AUTOSAR XML (schema 4-2-2)
package /STELLANTIS/EPT/ASWCs
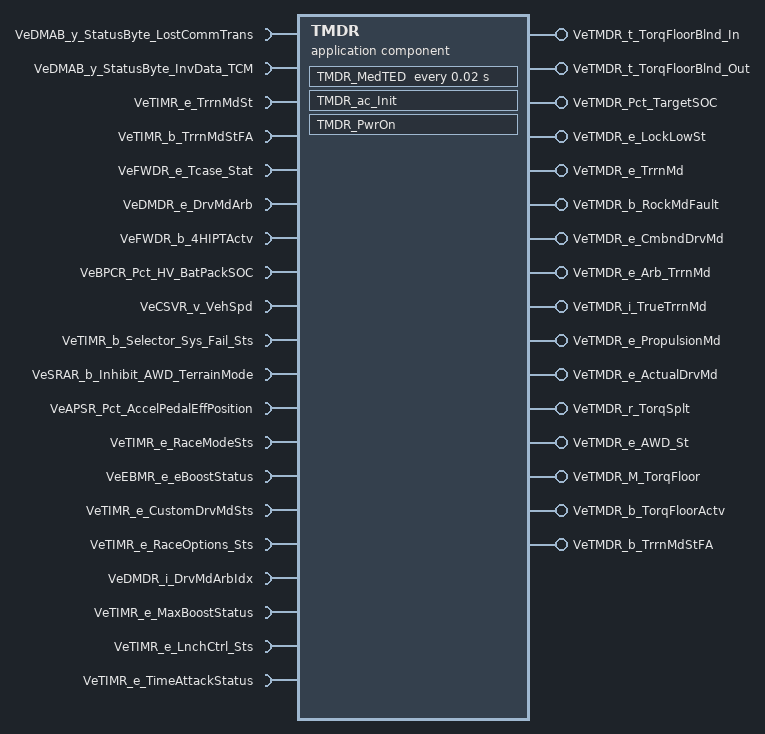
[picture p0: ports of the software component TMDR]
  application sw component type TMDR
    20 x require port:
      VeDMAB_y_StatusByte_LostCommTrans: variation-point={short-label=vpVeDMAB_y_StatusByte_LostCommTrans, sw-syscond=1}, nonqueued-receiver-com-spec{data-element=Value, init-value=0}, required-interface=VeDMAB_y_StatusByte_LostCommTrans
      VeDMAB_y_StatusByte_InvData_TCM: variation-point={short-label=vpVeDMAB_y_StatusByte_InvData_TCM, sw-syscond=1}, nonqueued-receiver-com-spec{data-element=Value, init-value=0}, required-interface=VeDMAB_y_StatusByte_InvData_TCM
      VeTIMR_e_TrrnMdSt: variation-point={short-label=vpVeTIMR_e_TrrnMdSt, sw-syscond=1}, nonqueued-receiver-com-spec{data-element=Value, init-value=CeTMDR_e_NotDefine}, required-interface=VeTIMR_e_TrrnMdSt
      VeTIMR_b_TrrnMdStFA: variation-point={short-label=vpVeTIMR_b_TrrnMdStFA, sw-syscond=1}, nonqueued-receiver-com-spec{data-element=Value, init-value=0}, required-interface=VeTIMR_b_TrrnMdStFA
      VeFWDR_e_Tcase_Stat: variation-point={short-label=vpVeFWDR_e_Tcase_Stat, sw-syscond=1}, nonqueued-receiver-com-spec{data-element=Value, init-value=CeFWDR_e_ShiftINProg}, required-interface=VeFWDR_e_Tcase_Stat
      VeDMDR_e_DrvMdArb: variation-point={short-label=vpVeDMDR_e_DrvMdArb, sw-syscond=1}, nonqueued-receiver-com-spec{data-element=Value, init-value=CeDMDR_e_NoDrvMd}, required-interface=VeDMDR_e_DrvMdArb
      VeFWDR_b_4HIPTActv: variation-point={short-label=vpVeFWDR_b_4HIPTActv, sw-syscond=1}, nonqueued-receiver-com-spec{data-element=Value, init-value=0}, required-interface=VeFWDR_b_4HIPTActv
      VeBPCR_Pct_HV_BatPackSOC: variation-point={short-label=vpVeBPCR_Pct_HV_BatPackSOC, sw-syscond=1}, nonqueued-receiver-com-spec{data-element=Value, init-value=0}, required-interface=VeBPCR_Pct_HV_BatPackSOC
      VeCSVR_v_VehSpd: variation-point={short-label=vpVeCSVR_v_VehSpd, sw-syscond=1}, nonqueued-receiver-com-spec{data-element=Value, init-value=0}, required-interface=VeCSVR_v_VehSpd
      VeTIMR_b_Selector_Sys_Fail_Sts: variation-point={short-label=vpVeTIMR_b_Selector_Sys_Fail_Sts, sw-syscond=1}, nonqueued-receiver-com-spec{data-element=Value, init-value=0}, required-interface=VeTIMR_b_Selector_Sys_Fail_Sts
      VeSRAR_b_Inhibit_AWD_TerrainMode: variation-point={short-label=vpVeSRAR_b_Inhibit_AWD_TerrainMode, sw-syscond=1}, nonqueued-receiver-com-spec{data-element=Value, init-value=0}, required-interface=VeSRAR_b_Inhibit_AWD_TerrainMode
      VeAPSR_Pct_AccelPedalEffPosition: variation-point={short-label=vpVeAPSR_Pct_AccelPedalEffPosition, sw-syscond=1}, nonqueued-receiver-com-spec{data-element=Value, init-value=0}, required-interface=VeAPSR_Pct_AccelPedalEffPosition
      VeTIMR_e_RaceModeSts: variation-point={short-label=vpVeTIMR_e_RaceModeSts, sw-syscond=1}, nonqueued-receiver-com-spec{data-element=Value, init-value=CeTIMR_e_RaceMode_Off}, required-interface=VeTIMR_e_RaceModeSts
      VeEBMR_e_eBoostStatus: variation-point={short-label=vpVeEBMR_e_eBoostStatus, sw-syscond=1}, nonqueued-receiver-com-spec{data-element=Value, init-value=CeEBMR_e_eBoostOFF}, required-interface=VeEBMR_e_eBoostStatus
      VeTIMR_e_CustomDrvMdSts: variation-point={short-label=vpVeTIMR_e_CustomDrvMdSts, sw-syscond=1}, nonqueued-receiver-com-spec{data-element=Value, init-value=CeTMDR_e_NotDefine}, required-interface=VeTIMR_e_CustomDrvMdSts
      VeTIMR_e_RaceOptions_Sts: variation-point={short-label=vpVeTIMR_e_RaceOptions_Sts, sw-syscond=1}, nonqueued-receiver-com-spec{data-element=Value, init-value=CeTIMR_e_NoOptionSelected}, required-interface=VeTIMR_e_RaceOptions_Sts
      VeDMDR_i_DrvMdArbIdx: variation-point={short-label=vpVeDMDR_i_DrvMdArbIdx, sw-syscond=1}, nonqueued-receiver-com-spec{data-element=Value, init-value=0}, required-interface=VeDMDR_i_DrvMdArbIdx
      VeTIMR_e_MaxBoostStatus: variation-point={short-label=vpVeTIMR_e_MaxBoostStatus, sw-syscond=1}, nonqueued-receiver-com-spec{data-element=Value, init-value=CeTIMR_e_Boost_Off}, required-interface=VeTIMR_e_MaxBoostStatus
      VeTIMR_e_LnchCtrl_Sts: variation-point={short-label=vpVeTIMR_e_LnchCtrl_Sts, sw-syscond=1}, nonqueued-receiver-com-spec{data-element=Value, init-value=CeTIMR_e_NOT_ALLOWED}, required-interface=VeTIMR_e_LnchCtrl_Sts
      VeTIMR_e_TimeAttackStatus: variation-point={short-label=vpVeTIMR_e_TimeAttackStatus, sw-syscond=1}, nonqueued-receiver-com-spec{data-element=Value, init-value=CeTIMR_e_Boost_Off}, required-interface=VeTIMR_e_TimeAttackStatus
    16 x provide port:
      VeTMDR_t_TorqFloorBlnd_In: nonqueued-sender-com-spec{data-element=Value, init-value=0}, provided-interface=VeTMDR_t_TorqFloorBlnd_In
      VeTMDR_t_TorqFloorBlnd_Out: nonqueued-sender-com-spec{data-element=Value, init-value=0}, provided-interface=VeTMDR_t_TorqFloorBlnd_Out
      VeTMDR_Pct_TargetSOC: nonqueued-sender-com-spec{data-element=Value, init-value=0}, provided-interface=VeTMDR_Pct_TargetSOC
      VeTMDR_e_LockLowSt: nonqueued-sender-com-spec{data-element=Value, init-value=CeTMDR_e_Off}, provided-interface=VeTMDR_e_LockLowSt
      VeTMDR_e_TrrnMd: nonqueued-sender-com-spec{data-element=Value, init-value=CeTMDR_e_NotDefine}, provided-interface=VeTMDR_e_TrrnMd
      VeTMDR_b_RockMdFault: nonqueued-sender-com-spec{data-element=Value, init-value=0}, provided-interface=VeTMDR_b_RockMdFault
      VeTMDR_e_CmbndDrvMd: nonqueued-sender-com-spec{data-element=Value, init-value=0}, provided-interface=VeTMDR_e_CmbndDrvMd
      VeTMDR_e_Arb_TrrnMd: nonqueued-sender-com-spec{data-element=Value, init-value=0}, provided-interface=VeTMDR_e_Arb_TrrnMd
      VeTMDR_i_TrueTrrnMd: nonqueued-sender-com-spec{data-element=Value, init-value=0}, provided-interface=VeTMDR_i_TrueTrrnMd
      VeTMDR_e_PropulsionMd: nonqueued-sender-com-spec{data-element=Value, init-value=CeTMDR_e_NotDefine}, provided-interface=VeTMDR_e_PropulsionMd
      VeTMDR_e_ActualDrvMd: nonqueued-sender-com-spec{data-element=Value, init-value=CeTMDR_e_NotDefine}, provided-interface=VeTMDR_e_ActualDrvMd
      VeTMDR_r_TorqSplt: nonqueued-sender-com-spec{data-element=Value, init-value=0}, provided-interface=VeTMDR_r_TorqSplt
      VeTMDR_e_AWD_St: nonqueued-sender-com-spec{data-element=Value, init-value=CeTMDR_e_AWD_BothAllowed}, provided-interface=VeTMDR_e_AWD_St
      VeTMDR_M_TorqFloor: nonqueued-sender-com-spec{data-element=Value, init-value=0}, provided-interface=VeTMDR_M_TorqFloor
      VeTMDR_b_TorqFloorActv: nonqueued-sender-com-spec{data-element=Value, init-value=0}, provided-interface=VeTMDR_b_TorqFloorActv
      VeTMDR_b_TrrnMdStFA: nonqueued-sender-com-spec{data-element=Value, init-value=0}, provided-interface=VeTMDR_b_TrrnMdStFA
    behavior IB_TMDR: data-type-mapping=msADTtoIDTMapping, handle-termination-and-restart=NO-SUPPORT, included-data-type-set=data-type=TeTMDR_e_StActv
      timing event Event_MedTED: start-on-event=TMDR_MedTED, period=0.02
      init event Event_TMDR_ac_Init: start-on-event=TMDR_ac_Init
      init event Event_PwrOn: start-on-event=TMDR_PwrOn
      runnable TMDR_ac_Init
        data-send-points:
          16 x access:
            OUT_VeTMDR_t_TorqFloorBlnd_In_Value: accessed-variable=VeTMDR_t_TorqFloorBlnd_In.Value
            OUT_VeTMDR_t_TorqFloorBlnd_Out_Value: accessed-variable=VeTMDR_t_TorqFloorBlnd_Out.Value
            OUT_VeTMDR_Pct_TargetSOC_Value: accessed-variable=VeTMDR_Pct_TargetSOC.Value
            OUT_VeTMDR_e_LockLowSt_Value: accessed-variable=VeTMDR_e_LockLowSt.Value
            OUT_VeTMDR_e_TrrnMd_Value: accessed-variable=VeTMDR_e_TrrnMd.Value
            OUT_VeTMDR_b_RockMdFault_Value: accessed-variable=VeTMDR_b_RockMdFault.Value
            OUT_VeTMDR_e_CmbndDrvMd_Value: accessed-variable=VeTMDR_e_CmbndDrvMd.Value
            OUT_VeTMDR_e_Arb_TrrnMd_Value: accessed-variable=VeTMDR_e_Arb_TrrnMd.Value
            OUT_VeTMDR_i_TrueTrrnMd_Value: accessed-variable=VeTMDR_i_TrueTrrnMd.Value
            OUT_VeTMDR_e_PropulsionMd_Value: accessed-variable=VeTMDR_e_PropulsionMd.Value
            OUT_VeTMDR_e_ActualDrvMd_Value: accessed-variable=VeTMDR_e_ActualDrvMd.Value
            OUT_VeTMDR_r_TorqSplt_Value: accessed-variable=VeTMDR_r_TorqSplt.Value
            OUT_VeTMDR_e_AWD_St_Value: accessed-variable=VeTMDR_e_AWD_St.Value
            OUT_VeTMDR_M_TorqFloor_Value: accessed-variable=VeTMDR_M_TorqFloor.Value
            OUT_VeTMDR_b_TorqFloorActv_Value: accessed-variable=VeTMDR_b_TorqFloorActv.Value
            OUT_VeTMDR_b_TrrnMdStFA_Value: accessed-variable=VeTMDR_b_TrrnMdStFA.Value
      runnable TMDR_PwrOn
        data-send-points:
          16 x access:
            OUT_VeTMDR_Pct_TargetSOC_Value: accessed-variable=VeTMDR_Pct_TargetSOC.Value
            OUT_VeTMDR_e_LockLowSt_Value: accessed-variable=VeTMDR_e_LockLowSt.Value
            OUT_VeTMDR_e_TrrnMd_Value: accessed-variable=VeTMDR_e_TrrnMd.Value
            OUT_VeTMDR_b_RockMdFault_Value: accessed-variable=VeTMDR_b_RockMdFault.Value
            OUT_VeTMDR_e_CmbndDrvMd_Value: accessed-variable=VeTMDR_e_CmbndDrvMd.Value
            OUT_VeTMDR_e_Arb_TrrnMd_Value: accessed-variable=VeTMDR_e_Arb_TrrnMd.Value
            OUT_VeTMDR_i_TrueTrrnMd_Value: accessed-variable=VeTMDR_i_TrueTrrnMd.Value
            OUT_VeTMDR_e_PropulsionMd_Value: accessed-variable=VeTMDR_e_PropulsionMd.Value
            OUT_VeTMDR_e_ActualDrvMd_Value: accessed-variable=VeTMDR_e_ActualDrvMd.Value
            OUT_VeTMDR_r_TorqSplt_Value: accessed-variable=VeTMDR_r_TorqSplt.Value
            OUT_VeTMDR_M_TorqFloor_Value: accessed-variable=VeTMDR_M_TorqFloor.Value
            OUT_VeTMDR_b_TorqFloorActv_Value: accessed-variable=VeTMDR_b_TorqFloorActv.Value
            OUT_VeTMDR_t_TorqFloorBlnd_In_Value: accessed-variable=VeTMDR_t_TorqFloorBlnd_In.Value
            OUT_VeTMDR_t_TorqFloorBlnd_Out_Value: accessed-variable=VeTMDR_t_TorqFloorBlnd_Out.Value
            OUT_VeTMDR_e_AWD_St_Value: accessed-variable=VeTMDR_e_AWD_St.Value
            OUT_VeTMDR_b_TrrnMdStFA_Value: accessed-variable=VeTMDR_b_TrrnMdStFA.Value
      runnable TMDR_MedTED
        data-receive-point-by-arguments:
          20 x access:
            IN_VeAPSR_Pct_AccelPedalEffPosition_Value: accessed-variable=VeAPSR_Pct_AccelPedalEffPosition.Value, variation-point={short-label=vpIN_VeAPSR_Pct_AccelPedalEffPosition_Value, sw-syscond=1}
            IN_VeBPCR_Pct_HV_BatPackSOC_Value: accessed-variable=VeBPCR_Pct_HV_BatPackSOC.Value, variation-point={short-label=vpIN_VeBPCR_Pct_HV_BatPackSOC_Value, sw-syscond=1}
            IN_VeCSVR_v_VehSpd_Value: accessed-variable=VeCSVR_v_VehSpd.Value, variation-point={short-label=vpIN_VeCSVR_v_VehSpd_Value, sw-syscond=1}
            IN_VeDMAB_y_StatusByte_InvData_TCM_Value: accessed-variable=VeDMAB_y_StatusByte_InvData_TCM.Value, variation-point={short-label=vpIN_VeDMAB_y_StatusByte_InvData_TCM_Value, sw-syscond=1}
            IN_VeDMAB_y_StatusByte_LostCommTrans_Value: accessed-variable=VeDMAB_y_StatusByte_LostCommTrans.Value, variation-point={short-label=vpIN_VeDMAB_y_StatusByte_LostCommTrans_Value, sw-syscond=1}
            IN_VeDMDR_e_DrvMdArb_Value: accessed-variable=VeDMDR_e_DrvMdArb.Value, variation-point={short-label=vpIN_VeDMDR_e_DrvMdArb_Value, sw-syscond=1}
            IN_VeDMDR_i_DrvMdArbIdx_Value: accessed-variable=VeDMDR_i_DrvMdArbIdx.Value, variation-point={short-label=vpIN_VeDMDR_i_DrvMdArbIdx_Value, sw-syscond=1}
            IN_VeEBMR_e_eBoostStatus_Value: accessed-variable=VeEBMR_e_eBoostStatus.Value, variation-point={short-label=vpIN_VeEBMR_e_eBoostStatus_Value, sw-syscond=1}
            IN_VeFWDR_b_4HIPTActv_Value: accessed-variable=VeFWDR_b_4HIPTActv.Value, variation-point={short-label=vpIN_VeFWDR_b_4HIPTActv_Value, sw-syscond=1}
            IN_VeFWDR_e_Tcase_Stat_Value: accessed-variable=VeFWDR_e_Tcase_Stat.Value, variation-point={short-label=vpIN_VeFWDR_e_Tcase_Stat_Value, sw-syscond=1}
            IN_VeSRAR_b_Inhibit_AWD_TerrainMode_Value: accessed-variable=VeSRAR_b_Inhibit_AWD_TerrainMode.Value, variation-point={short-label=vpIN_VeSRAR_b_Inhibit_AWD_TerrainMode_Value, sw-syscond=1}
            IN_VeTIMR_b_Selector_Sys_Fail_Sts_Value: accessed-variable=VeTIMR_b_Selector_Sys_Fail_Sts.Value, variation-point={short-label=vpIN_VeTIMR_b_Selector_Sys_Fail_Sts_Value, sw-syscond=1}
            IN_VeTIMR_b_TrrnMdStFA_Value: accessed-variable=VeTIMR_b_TrrnMdStFA.Value, variation-point={short-label=vpIN_VeTIMR_b_TrrnMdStFA_Value, sw-syscond=1}
            IN_VeTIMR_e_CustomDrvMdSts_Value: accessed-variable=VeTIMR_e_CustomDrvMdSts.Value, variation-point={short-label=vpIN_VeTIMR_e_CustomDrvMdSts_Value, sw-syscond=1}
            IN_VeTIMR_e_LnchCtrl_Sts_Value: accessed-variable=VeTIMR_e_LnchCtrl_Sts.Value, variation-point={short-label=vpIN_VeTIMR_e_LnchCtrl_Sts_Value, sw-syscond=1}
            IN_VeTIMR_e_MaxBoostStatus_Value: accessed-variable=VeTIMR_e_MaxBoostStatus.Value, variation-point={short-label=vpIN_VeTIMR_e_MaxBoostStatus_Value, sw-syscond=1}
            IN_VeTIMR_e_RaceModeSts_Value: accessed-variable=VeTIMR_e_RaceModeSts.Value, variation-point={short-label=vpIN_VeTIMR_e_RaceModeSts_Value, sw-syscond=1}
            IN_VeTIMR_e_RaceOptions_Sts_Value: accessed-variable=VeTIMR_e_RaceOptions_Sts.Value, variation-point={short-label=vpIN_VeTIMR_e_RaceOptions_Sts_Value, sw-syscond=1}
            IN_VeTIMR_e_TimeAttackStatus_Value: accessed-variable=VeTIMR_e_TimeAttackStatus.Value, variation-point={short-label=vpIN_VeTIMR_e_TimeAttackStatus_Value, sw-syscond=1}
            IN_VeTIMR_e_TrrnMdSt_Value: accessed-variable=VeTIMR_e_TrrnMdSt.Value, variation-point={short-label=vpIN_VeTIMR_e_TrrnMdSt_Value, sw-syscond=1}
        data-send-points:
          14 x access:
            OUT_VeTMDR_Pct_TargetSOC_Value: accessed-variable=VeTMDR_Pct_TargetSOC.Value
            OUT_VeTMDR_e_LockLowSt_Value: accessed-variable=VeTMDR_e_LockLowSt.Value
            OUT_VeTMDR_e_TrrnMd_Value: accessed-variable=VeTMDR_e_TrrnMd.Value
            OUT_VeTMDR_b_RockMdFault_Value: accessed-variable=VeTMDR_b_RockMdFault.Value
            OUT_VeTMDR_e_CmbndDrvMd_Value: accessed-variable=VeTMDR_e_CmbndDrvMd.Value
            OUT_VeTMDR_e_Arb_TrrnMd_Value: accessed-variable=VeTMDR_e_Arb_TrrnMd.Value
            OUT_VeTMDR_i_TrueTrrnMd_Value: accessed-variable=VeTMDR_i_TrueTrrnMd.Value
            OUT_VeTMDR_e_PropulsionMd_Value: accessed-variable=VeTMDR_e_PropulsionMd.Value
            OUT_VeTMDR_e_ActualDrvMd_Value: accessed-variable=VeTMDR_e_ActualDrvMd.Value
            OUT_VeTMDR_r_TorqSplt_Value: accessed-variable=VeTMDR_r_TorqSplt.Value
            OUT_VeTMDR_e_AWD_St_Value: accessed-variable=VeTMDR_e_AWD_St.Value
            OUT_VeTMDR_M_TorqFloor_Value: accessed-variable=VeTMDR_M_TorqFloor.Value
            OUT_VeTMDR_b_TorqFloorActv_Value: accessed-variable=VeTMDR_b_TorqFloorActv.Value
            OUT_VeTMDR_b_TrrnMdStFA_Value: accessed-variable=VeTMDR_b_TrrnMdStFA.Value
      6 x variation point proxy, all with category=CONDITION:
        Variant_TMDR_BEV_REPBSelec: condition-access=1
        Variant_TMDR_COREBEVSelec: condition-access=1
        Variant_TMDR_FUNC_Selec: condition-access=0
        Variant_TMDR_M182TrrnMd: condition-access=0
        Variant_TMDR_MSG_Selec: condition-access=1
        Variant_TMDR_REPBSelec: condition-access=0
